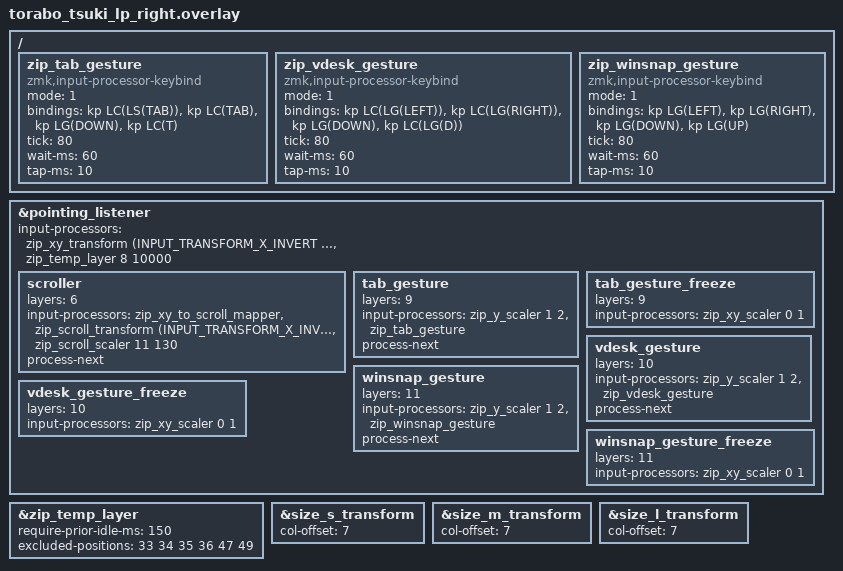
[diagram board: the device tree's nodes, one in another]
#include "torabo_tsuki_lp.dtsi"
#include <input/processors.dtsi>
#include <input/processors/zmk-input-processor-keybind.dtsi>
#include <dt-bindings/zmk/input_transform.h>

/ {
	zip_tab_gesture: zip_tab_gesture {
		compatible = "zmk,input-processor-keybind";
		#input-processor-cells = <0>;
		mode = <1>;
		bindings =
			<&kp LC(LS(TAB))>,  // [0] 左 → 前のタブ（Ctrl+Shift+Tab）
			<&kp LC(TAB)>,      // [1] 右 → 次のタブ（Ctrl+Tab）
			<&kp LG(DOWN)>,     // [2] 下 → 最小化（Win+↓）
			<&kp LC(T)>;        // [3] 上 → 新しいタブ（Ctrl+T）
		tick = <80>;
		wait-ms = <60>;
		tap-ms = <10>;
	};

	zip_vdesk_gesture: zip_vdesk_gesture {
		compatible = "zmk,input-processor-keybind";
		#input-processor-cells = <0>;
		mode = <1>;
		bindings =
			<&kp LC(LG(LEFT))>,  // [0] 左 → 前のデスクトップ（Ctrl+Win+←）
			<&kp LC(LG(RIGHT))>, // [1] 右 → 次のデスクトップ（Ctrl+Win+→）
			<&kp LG(DOWN)>,      // [2] 下 → 最小化（Win+↓）
			<&kp LC(LG(D))>;     // [3] 上 → 新しいデスクトップ（Ctrl+Win+D）
		tick = <80>;
		wait-ms = <60>;
		tap-ms = <10>;
	};

	zip_winsnap_gesture: zip_winsnap_gesture {
		compatible = "zmk,input-processor-keybind";
		#input-processor-cells = <0>;
		mode = <1>;
		bindings =
			<&kp LG(LEFT)>,   // [0] 左 → 左に寄せる（Win+←）
			<&kp LG(RIGHT)>,  // [1] 右 → 右に寄せる（Win+→）
			<&kp LG(DOWN)>,   // [2] 下 → 元に戻す・最小化（Win+↓）
			<&kp LG(UP)>;     // [3] 上 → 最大化（Win+↑）
		tick = <80>;
		wait-ms = <60>;
		tap-ms = <10>;
	};
};

&pointing_listener {
	input-processors = <&zip_xy_transform (INPUT_TRANSFORM_X_INVERT | INPUT_TRANSFORM_Y_INVERT)>,
		<&zip_temp_layer 8 10000>;

	scroller {
		layers = <6>;
		input-processors = <&zip_xy_to_scroll_mapper>,
			<&zip_scroll_transform (INPUT_TRANSFORM_X_INVERT)>,
			<&zip_scroll_scaler 11 130>;
		process-next;
	};

	tab_gesture {
		layers = <9>;
		input-processors = <&zip_y_scaler 1 2>, <&zip_tab_gesture>;
		process-next;
	};

	tab_gesture_freeze {
		layers = <9>;
		input-processors = <&zip_xy_scaler 0 1>;
	};

	vdesk_gesture {
		layers = <10>;
		input-processors = <&zip_y_scaler 1 2>, <&zip_vdesk_gesture>;
		process-next;
	};

	vdesk_gesture_freeze {
		layers = <10>;
		input-processors = <&zip_xy_scaler 0 1>;
	};

	winsnap_gesture {
		layers = <11>;
		input-processors = <&zip_y_scaler 1 2>, <&zip_winsnap_gesture>;
		process-next;
	};

	winsnap_gesture_freeze {
		layers = <11>;
		input-processors = <&zip_xy_scaler 0 1>;
	};
};

&zip_temp_layer {
	require-prior-idle-ms = <150>;
	excluded-positions = <33 34 35 36 47 49>; // J K L / ⇧(Shift 36) / MB4(47) / MB5(49)
};

&size_s_transform {
	col-offset = <7>;
};

&size_m_transform {
	col-offset = <7>;
};

&size_l_transform {
	col-offset = <7>;
};
